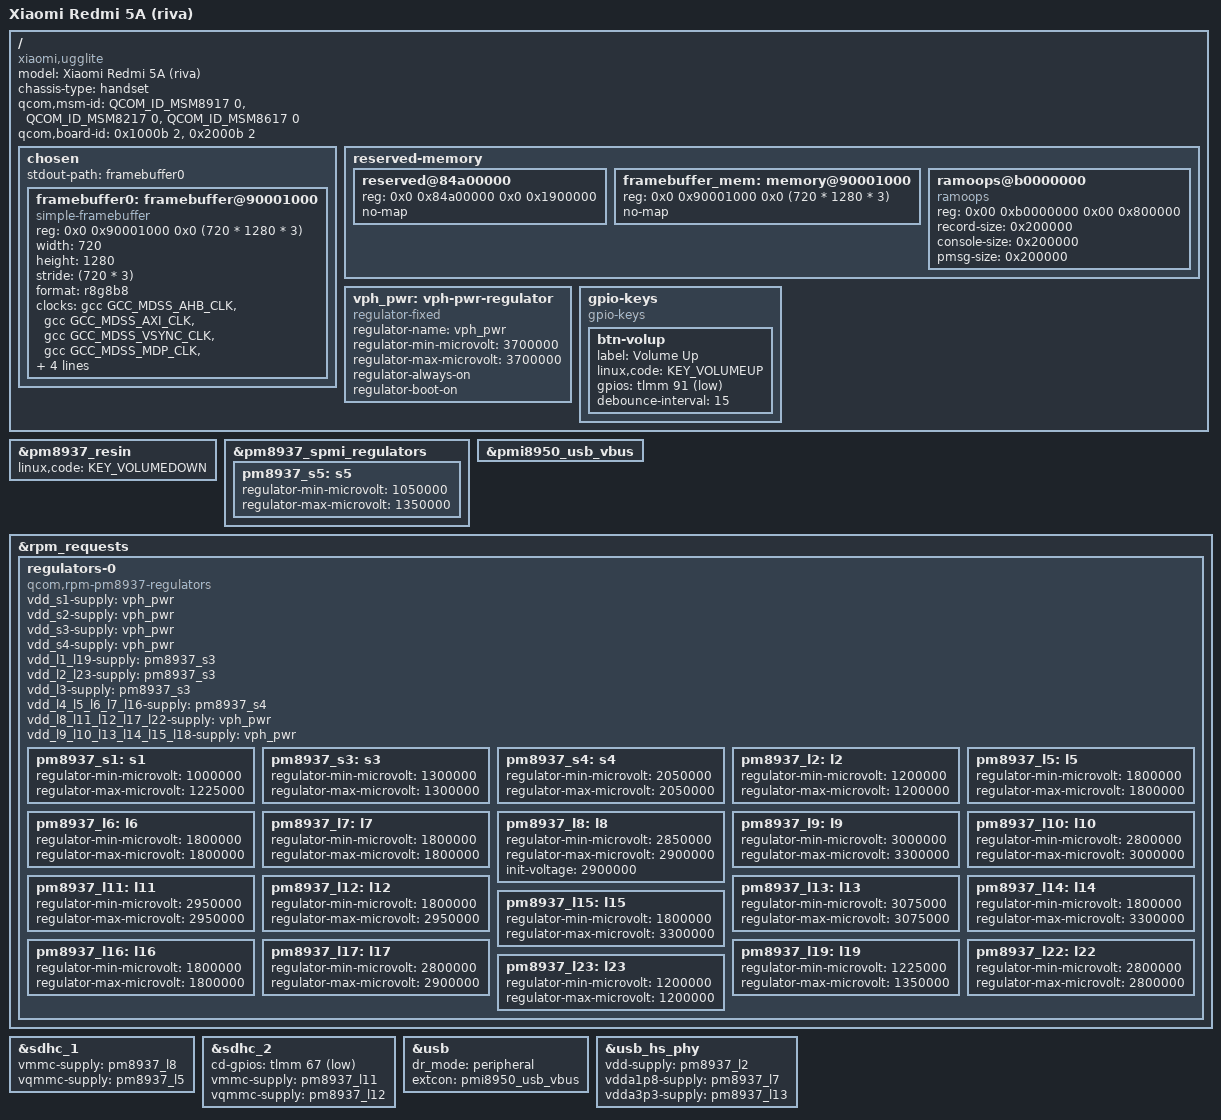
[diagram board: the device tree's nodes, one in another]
// SPDX-License-Identifier: BSD-3-Clause
/*
 * Copyright (c) 2023, Barnabas Czeman
 */

/dts-v1/;

#include <dt-bindings/arm/qcom,ids.h>
#include <dt-bindings/gpio/gpio.h>
#include <dt-bindings/input/linux-event-codes.h>
#include <dt-bindings/leds/common.h>
#include "msm8917.dtsi"
#include "pm8937.dtsi"
#include "pmi8950.dtsi"

/ {
	model = "Xiaomi Redmi 5A (riva)";
	compatible = "xiaomi,ugglite", "qcom,msm8917";
	chassis-type = "handset";

	qcom,msm-id = <QCOM_ID_MSM8917 0>,
		<QCOM_ID_MSM8217 0>,
		<QCOM_ID_MSM8617 0>;
	qcom,board-id = <0x1000b 2>, <0x2000b 2>;

	chosen {
		#address-cells = <2>;
		#size-cells = <2>;
		ranges;

		stdout-path = "framebuffer0";

		framebuffer0: framebuffer@90001000 {
			compatible = "simple-framebuffer";
			reg = <0x0 0x90001000 0x0 (720 * 1280 * 3)>;
			width = <720>;
			height = <1280>;
			stride = <(720 * 3)>;
			format = "r8g8b8";

			clocks = <&gcc GCC_MDSS_AHB_CLK>,
				 <&gcc GCC_MDSS_AXI_CLK>,
				 <&gcc GCC_MDSS_VSYNC_CLK>,
				 <&gcc GCC_MDSS_MDP_CLK>,
				 <&gcc GCC_MDSS_BYTE0_CLK>,
				 <&gcc GCC_MDSS_PCLK0_CLK>,
				 <&gcc GCC_MDSS_ESC0_CLK>;
			power-domains = <&gcc MDSS_GDSC>;
		};
	};

	reserved-memory {
		/delete-node/ reserved@85b00000;

		reserved@84a00000 {
			reg = <0x0 0x84a00000 0x0 0x1900000>;
			no-map;
		};

		framebuffer_mem: memory@90001000 {
			reg = <0x0 0x90001000 0x0 (720 * 1280 * 3)>;
			no-map;
		};

		ramoops@b0000000 {
		  compatible = "ramoops";
		  reg = <0x00 0xb0000000 0x00 0x800000>;
		  record-size = <0x200000>;
		  console-size = <0x200000>;
		  pmsg-size = <0x200000>;
		};
	};

	vph_pwr: vph-pwr-regulator {
		compatible = "regulator-fixed";
		regulator-name = "vph_pwr";
		regulator-min-microvolt = <3700000>;
		regulator-max-microvolt = <3700000>;
		regulator-always-on;
		regulator-boot-on;
	};

	gpio-keys {
		compatible = "gpio-keys";

		btn-volup {
			label = "Volume Up";
			linux,code = <KEY_VOLUMEUP>;
			gpios = <&tlmm 91 GPIO_ACTIVE_LOW>;
			debounce-interval = <15>;
		};
	};
};

&pm8937_resin {
	linux,code = <KEY_VOLUMEDOWN>;
	status = "okay";
};

&pm8937_spmi_regulators {
	pm8937_s5: s5 {
		regulator-min-microvolt = <1050000>;
		regulator-max-microvolt = <1350000>;
	};
};

&pmi8950_usb_vbus {
	status = "okay";
};

&rpm_requests {
	regulators-0 {
		compatible = "qcom,rpm-pm8937-regulators";

		vdd_s1-supply = <&vph_pwr>;
		vdd_s2-supply = <&vph_pwr>;
		vdd_s3-supply = <&vph_pwr>;
		vdd_s4-supply = <&vph_pwr>;

		vdd_l1_l19-supply = <&pm8937_s3>;
		vdd_l2_l23-supply = <&pm8937_s3>;
		vdd_l3-supply = <&pm8937_s3>;
		vdd_l4_l5_l6_l7_l16-supply = <&pm8937_s4>;
		vdd_l8_l11_l12_l17_l22-supply = <&vph_pwr>;
		vdd_l9_l10_l13_l14_l15_l18-supply = <&vph_pwr>;

		pm8937_s1: s1 {
			regulator-min-microvolt = <1000000>;
			regulator-max-microvolt = <1225000>;
		};

		pm8937_s3: s3 {
			regulator-min-microvolt = <1300000>;
			regulator-max-microvolt = <1300000>;
		};

		pm8937_s4: s4 {
			regulator-min-microvolt = <2050000>;
			regulator-max-microvolt = <2050000>;
		};

		pm8937_l2: l2 {
			regulator-min-microvolt = <1200000>;
			regulator-max-microvolt = <1200000>;
		};

		pm8937_l5: l5 {
			regulator-min-microvolt = <1800000>;
			regulator-max-microvolt = <1800000>;
		};

		pm8937_l6: l6 {
			regulator-min-microvolt = <1800000>;
			regulator-max-microvolt = <1800000>;
		};

		pm8937_l7: l7 {
			regulator-min-microvolt = <1800000>;
			regulator-max-microvolt = <1800000>;
		};

		pm8937_l8: l8 {
			regulator-min-microvolt = <2850000>;
			regulator-max-microvolt = <2900000>;
			init-voltage = <2900000>;
		};

		pm8937_l9: l9 {
			regulator-min-microvolt = <3000000>;
			regulator-max-microvolt = <3300000>;
		};

		pm8937_l10: l10 {
			regulator-min-microvolt = <2800000>;
			regulator-max-microvolt = <3000000>;
		};

		pm8937_l11: l11 {
			regulator-min-microvolt = <2950000>;
			regulator-max-microvolt = <2950000>;
		};

		pm8937_l12: l12 {
			regulator-min-microvolt = <1800000>;
			regulator-max-microvolt = <2950000>;
		};

		pm8937_l13: l13 {
			regulator-min-microvolt = <3075000>;
			regulator-max-microvolt = <3075000>;
		};

		pm8937_l14: l14 {
			regulator-min-microvolt = <1800000>;
			regulator-max-microvolt = <3300000>;
		};

		pm8937_l15: l15 {
			regulator-min-microvolt = <1800000>;
			regulator-max-microvolt = <3300000>;
		};

		pm8937_l16: l16 {
			regulator-min-microvolt = <1800000>;
			regulator-max-microvolt = <1800000>;
		};

		pm8937_l17: l17 {
			regulator-min-microvolt = <2800000>;
			regulator-max-microvolt = <2900000>;
		};

		pm8937_l19: l19 {
			regulator-min-microvolt = <1225000>;
			regulator-max-microvolt = <1350000>;
		};

		pm8937_l22: l22 {
			regulator-min-microvolt = <2800000>;
			regulator-max-microvolt = <2800000>;
		};

		pm8937_l23: l23 {
			regulator-min-microvolt = <1200000>;
			regulator-max-microvolt = <1200000>;
		};
	};
};

&sdhc_1 {
	vmmc-supply = <&pm8937_l8>;
	vqmmc-supply = <&pm8937_l5>;
	status = "okay";
};

&sdhc_2 {
	cd-gpios = <&tlmm 67 GPIO_ACTIVE_LOW>;
	vmmc-supply = <&pm8937_l11>;
	vqmmc-supply = <&pm8937_l12>;
	status = "okay";
};

&usb {
	dr_mode = "peripheral";
	extcon = <&pmi8950_usb_vbus>;
	status = "okay";
};

&usb_hs_phy {
	vdd-supply = <&pm8937_l2>;
	vdda1p8-supply = <&pm8937_l7>;
	vdda3p3-supply = <&pm8937_l13>;
	status = "okay";
};
